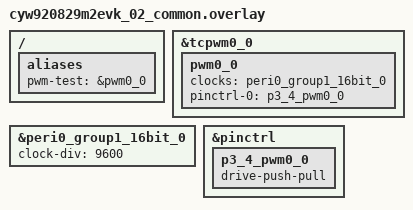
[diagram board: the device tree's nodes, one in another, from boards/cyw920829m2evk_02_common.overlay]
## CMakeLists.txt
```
# SPDX-License-Identifier: Apache-2.0

cmake_minimum_required(VERSION 3.28.0)
find_package(Zephyr REQUIRED HINTS $ENV{ZEPHYR_BASE})
project(pwm_api)

FILE(GLOB app_sources src/*.c)
target_sources(app PRIVATE ${app_sources})
```

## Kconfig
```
# Copyright (c) 2025 Tenstorrent AI ULC
# SPDX-License-Identifier: Apache-2.0

mainmenu "PWM GPIO API test"

source "Kconfig.zephyr"

config DEFAULT_PWM_PORT
	int "Default PWM port/channel"
	default 1 if PWM_STM32 || PWM_MCHP_G1_TCC || PWM_MCHP_TC_G1
	default 0
	help
	  PWM port matching the channel associated with PWM pin.

config INVALID_PWM_PORT
	int "Invalid PWM port/channel"
	default 9 if PWM_NRFX || PWM_MCHP_G1_TCC || PWM_MCHP_TC_G1
	default -1
	help
	  Invalid PWM port/channel for negative testing.

config DEFAULT_PERIOD_CYCLE
	int "Default PWM period in cycles"
	default 1024 if SOC_MK64F12 || SOC_MKW41Z4 || SOC_ESP32S2 || SOC_ESP32S3 || SOC_ESP32C3
	default 32768 if PWM_INTEL_BLINKY
	default 64000
	help
	  Default PWM period in clock cycles.

config DEFAULT_PULSE_CYCLE
	int "Default PWM pulse in cycles"
	default 512 if SOC_MK64F12 || SOC_MKW41Z4 || SOC_ESP32S2 || SOC_ESP32S3 || SOC_ESP32C3
	default 16384 if PWM_INTEL_BLINKY
	default 32000
	help
	  Default PWM pulse in clock cycles.

config DEFAULT_PERIOD_NSEC
	int "Default PWM period in nanoseconds"
	default 4000000 if SOC_FAMILY_MCXW
	default 546000 if PWM_MCHP_G1_TCC
	default 2000000
	help
	  Default PWM period in nanoseconds.

config DEFAULT_PULSE_NSEC
	int "Default PWM pulse in nanoseconds"
	default 500000 if SOC_MK64F12 || SOC_MKW41Z4 || SOC_ESP32S2 || SOC_ESP32S3 || SOC_ESP32C3
	default 500000 if PWM_INTEL_BLINKY
	default 2000000 if SOC_FAMILY_MCXW
	default 273000 if PWM_MCHP_G1_TCC
	default 1000000
	help
	  Default PWM pulse in nanoseconds.
```

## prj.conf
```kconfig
CONFIG_PWM=y
CONFIG_ZTEST=y
CONFIG_TEST_USERSPACE=y
```

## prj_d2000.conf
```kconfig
CONFIG_PWM=y
CONFIG_PINMUX=y
CONFIG_PWM_QMSI_NUM_PORTS=2
CONFIG_ZTEST=y
```

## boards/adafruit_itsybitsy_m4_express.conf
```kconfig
CONFIG_DEFAULT_PWM_PORT=2 # TCC1/WO[2] on PA18 (D7)
```

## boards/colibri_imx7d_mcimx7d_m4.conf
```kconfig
CONFIG_DEFAULT_PERIOD_CYCLE=1024
CONFIG_DEFAULT_PULSE_CYCLE=512
CONFIG_DEFAULT_PERIOD_NSEC=2000000
CONFIG_DEFAULT_PULSE_NSEC=500000
```

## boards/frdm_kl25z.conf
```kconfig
# Copyright (c) 2026 Gabriel Ivo <gabriel.bozi@usp.br>
#
# SPDX-License-Identifier: Apache-2.0

CONFIG_DEFAULT_PERIOD_CYCLE=1024
CONFIG_DEFAULT_PULSE_CYCLE=512
CONFIG_DEFAULT_PERIOD_NSEC=1000000
CONFIG_DEFAULT_PULSE_NSEC=500000
```

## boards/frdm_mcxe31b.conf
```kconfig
# Copyright 2026 NXP
# SPDX-License-Identifier: Apache-2.0

# Use eMIOS channel 3 (OPWFMB, internal counter, 10 MHz) as PWM test output.
CONFIG_DEFAULT_PWM_PORT=3
```

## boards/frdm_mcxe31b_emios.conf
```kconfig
# SPDX-FileCopyrightText: Copyright 2026 NXP
# SPDX-License-Identifier: Apache-2.0

# Use eMIOS channel 3 (OPWFMB, internal counter, 10 MHz) as PWM test output.
CONFIG_DEFAULT_PWM_PORT=3
```

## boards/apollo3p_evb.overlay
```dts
/*
 * SPDX-License-Identifier: Apache-2.0
 *
 * Copyright (c) 2025 Ambiq
 */

/ {
	aliases {
		pwm-0 = &pwm2;
	};
};

&pwm2 {
	status = "okay";
};
```

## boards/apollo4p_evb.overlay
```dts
/*
 * SPDX-License-Identifier: Apache-2.0
 *
 * Copyright (c) 2025 Ambiq
 */

/ {
	aliases {
		pwm-test = &pwm2;
	};
};

&pwm2 {
	status = "okay";
};
```

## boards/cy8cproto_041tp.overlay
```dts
/*
 * SPDX-FileCopyrightText: Copyright (c) 2026 Infineon Technologies AG,
 * SPDX-FileCopyrightText: or an affiliate of Infineon Technologies AG. All rights reserved.
 *
 * SPDX-License-Identifier: Apache-2.0
 */

#include <zephyr/dt-bindings/pwm/pwm.h>

/ {
	aliases {
		pwm-test = &pwm0_0;
	};
};

&tcpwm0_0 {
	status = "okay";

	pwm0_0 {
		clocks = <&peri_clk_div3>;
		status = "okay";
		pinctrl-0 = <&p3_1_pwm0_0>;
		pinctrl-names = "default";
	};
};

&p3_1_pwm0_0 {
	drive-push-pull;
};

&peri_clk_div3 {
	status = "okay";
};
```

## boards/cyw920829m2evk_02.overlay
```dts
/*
 * Copyright (c) 2025 Infineon Technologies AG,
 * or an affiliate of Infineon Technologies AG.
 *
 * SPDX-License-Identifier: Apache-2.0
 */

#include <zephyr/dt-bindings/pwm/pwm.h>
#include <zephyr/dt-bindings/pwm/pwm_ifx_tcpwm.h>

/ {
	aliases {
		pwm-test = &pwm0_0;
	};
};

&tcpwm0_0 {
	status = "okay";
	divider-type = <PWM_IFX_SYSCLK_DIV_16_BIT>;
	divider-sel = <1>;
	divider-val = <9599>;

	pwm0_0: pwm0_0 {
		status = "okay";
		pinctrl-0 = <&p3_4_pwm0_0>;
		pinctrl-names = "default";
	};
};

&pinctrl {
	p3_4_pwm0_0: p3_4_pwm0_0 {
		drive-push-pull;
	};
};
```

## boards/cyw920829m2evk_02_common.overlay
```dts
/*
 * SPDX-FileCopyrightText: Copyright (c) 2026 Infineon Technologies AG,
 * SPDX-FileCopyrightText: or an affiliate of Infineon Technologies AG. All rights reserved.
 *
 * SPDX-License-Identifier: Apache-2.0
 */

#include <zephyr/dt-bindings/pwm/pwm.h>
#include <zephyr/dt-bindings/pwm/pwm_ifx_tcpwm.h>

/ {
	aliases {
		pwm-test = &pwm0_0;
	};
};

&tcpwm0_0 {
	status = "okay";

	pwm0_0: pwm0_0 {
		status = "okay";
		clocks = <&peri0_group1_16bit_0>;
		pinctrl-0 = <&p3_4_pwm0_0>;
		pinctrl-names = "default";
	};
};

&peri0_group1_16bit_0 {
	status = "okay";
	clock-div = <9600>;
};

&pinctrl {
	p3_4_pwm0_0: p3_4_pwm0_0 {
		drive-push-pull;
	};
};
```

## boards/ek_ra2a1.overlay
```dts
/*
 * Copyright (c) 2025 Renesas Electronics Corporation
 *
 * SPDX-License-Identifier: Apache-2.0
 */

/ {
	aliases {
		pwm-test = &pwm0;
	};
};
```

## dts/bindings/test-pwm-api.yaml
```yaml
#
# Copyright (c) 2024 Espressif Systems (Shanghai) Co., Ltd.
#
# SPDX-License-Identifier: Apache-2.0
#

description: |
    This binding provides resources required to build and run the test
    tests/drivers/pwm/pwm_api when CONFIG_ENABLE_TIMING_CHECK is enabled.

compatible: "test-pwm-api"

properties:
  in-gpios:
    type: phandle-array
    required: true
    description: |
      GPIO to be used as input to check and validate PWM timing.
```

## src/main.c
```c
/*
 * Copyright (c) 2016 Intel Corporation
 *
 * SPDX-License-Identifier: Apache-2.0
 */


#include <zephyr/kernel.h>
#include <zephyr/ztest.h>
#include <zephyr/device.h>

const struct device *get_pwm_device(void);

static void *pwm_basic_setup(void)
{
	const struct device *dev = get_pwm_device();

	zassert_true(device_is_ready(dev), "PWM device is not ready");
	k_object_access_grant(dev, k_current_get());

	return NULL;
}

ZTEST_SUITE(pwm_basic, NULL, pwm_basic_setup, NULL, NULL, NULL);
```

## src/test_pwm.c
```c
/*
 * Copyright (c) 2016 Intel Corporation.
 *
 * SPDX-License-Identifier: Apache-2.0
 */

/**
 * @file
 * @brief Verify PWM can work well when configure through nsec,
 * or cycle.
 *
 * @details
 * - Test Steps
 *   -# Bind PWM_0 port 0.
 *   -# Set PWM period and pulse using pwm_set_cycles() or pwm_set().
 *   -# Use multimeter or other instruments to measure the output
 *	from PWM_OUT_0.
 * - Expected Results
 *   -# The output of PWM_OUT_0 will differ according to the value
 *	of period and pulse.
 *	Always on  ->  Period : Pulse (1 : 1)  ->  3.3V
 *	Half on  ->  Period : Pulse (2 : 1)  ->  1.65V
 *	Always off  ->  Period : Pulse (1 : 0)  ->  0V
 */

#include <zephyr/device.h>
#include <inttypes.h>
#include <zephyr/drivers/pwm.h>
#include <zephyr/kernel.h>
#include <zephyr/ztest.h>

#if DT_NODE_HAS_STATUS_OKAY(DT_ALIAS(pwm_test))
#define PWM_DEV_NODE DT_ALIAS(pwm_test)
#else
#error "Test requires a pwm-test alias in DTS"
#endif

#define DEFAULT_PERIOD_CYCLE CONFIG_DEFAULT_PERIOD_CYCLE
#define DEFAULT_PULSE_CYCLE  CONFIG_DEFAULT_PULSE_CYCLE
#define DEFAULT_PERIOD_NSEC  CONFIG_DEFAULT_PERIOD_NSEC
#define DEFAULT_PULSE_NSEC   CONFIG_DEFAULT_PULSE_NSEC

#if DT_HAS_COMPAT_STATUS_OKAY(zephyr_fake_pwm)
#include <zephyr/fff.h>
DEFINE_FFF_GLOBALS;
#endif

#define DEFAULT_PWM_PORT CONFIG_DEFAULT_PWM_PORT
#define INVALID_PWM_PORT CONFIG_INVALID_PWM_PORT

#define UNIT_CYCLES	0
#define UNIT_NSECS	1

const struct device *get_pwm_device(void)
{
	return DEVICE_DT_GET(PWM_DEV_NODE);
}

static int test_task(uint32_t port, uint32_t period, uint32_t pulse, uint8_t unit)
{
	TC_PRINT("[PWM]: %" PRIu8 ", [period]: %" PRIu32 ", [pulse]: %" PRIu32 "\n",
		port, period, pulse);

	const struct device *pwm_dev = get_pwm_device();

	if (!device_is_ready(pwm_dev)) {
		TC_PRINT("PWM device is not ready\n");
		return TC_FAIL;
	}

	if (unit == UNIT_CYCLES) {
		/* Verify pwm_set_cycles() */
		if (pwm_set_cycles(pwm_dev, port, period, pulse, 0)) {
			TC_PRINT("Fail to set the period and pulse width\n");
			return TC_FAIL;
		}
	} else { /* unit == UNIT_NSECS */
		/* Verify pwm_set() */
		if (pwm_set(pwm_dev, port, period, pulse, 0)) {
			TC_PRINT("Fail to set the period and pulse width\n");
			return TC_FAIL;
		}
	}

	return TC_PASS;
}

ZTEST_USER(pwm_basic, test_pwm_nsec)
{
	/* Period : Pulse (2000000 : 1000000), unit (nsec). Voltage : 1.65V */
	zassert_true(test_task(DEFAULT_PWM_PORT, DEFAULT_PERIOD_NSEC,
				DEFAULT_PULSE_NSEC, UNIT_NSECS) == TC_PASS);
	k_sleep(K_MSEC(1000));

	/* Period : Pulse (2000000 : 2000000), unit (nsec). Voltage : 3.3V */
	zassert_true(test_task(DEFAULT_PWM_PORT, DEFAULT_PERIOD_NSEC,
				DEFAULT_PERIOD_NSEC, UNIT_NSECS) == TC_PASS);
	k_sleep(K_MSEC(1000));

	/* Period : Pulse (2000000 : 0), unit (nsec). Voltage : 0V */
	zassert_true(test_task(DEFAULT_PWM_PORT, DEFAULT_PERIOD_NSEC,
				0, UNIT_NSECS) == TC_PASS);
	k_sleep(K_MSEC(1000));
}

ZTEST_USER(pwm_basic, test_pwm_cycle)
{
	/* Period : Pulse (64000 : 32000), unit (cycle). Voltage : 1.65V */
	zassert_true(test_task(DEFAULT_PWM_PORT, DEFAULT_PERIOD_CYCLE,
				DEFAULT_PULSE_CYCLE, UNIT_CYCLES) == TC_PASS);
	k_sleep(K_MSEC(1000));

	/* Period : Pulse (64000 : 64000), unit (cycle). Voltage : 3.3V */
	zassert_true(test_task(DEFAULT_PWM_PORT, DEFAULT_PERIOD_CYCLE,
				DEFAULT_PERIOD_CYCLE, UNIT_CYCLES) == TC_PASS);
	k_sleep(K_MSEC(1000));

	/* Period : Pulse (64000 : 0), unit (cycle). Voltage : 0V */
	zassert_true(test_task(DEFAULT_PWM_PORT, DEFAULT_PERIOD_CYCLE,
				0, UNIT_CYCLES) == TC_PASS);
	k_sleep(K_MSEC(1000));
}

#if (CONFIG_INVALID_PWM_PORT >= 0)
ZTEST_USER(pwm_basic, test_pwm_invalid_port)
{
	const struct device *pwm_dev = get_pwm_device();

	TC_PRINT("[PWM]: %" PRIu8 ", [period]: %" PRIu32 ", [pulse]: %" PRIu32 "\n",
		INVALID_PWM_PORT, DEFAULT_PERIOD_CYCLE, DEFAULT_PULSE_CYCLE);

	zassert_true(device_is_ready(pwm_dev), "PWM device is not ready");

	zassert_equal(pwm_set_cycles(pwm_dev, INVALID_PWM_PORT, DEFAULT_PERIOD_CYCLE,
				     DEFAULT_PULSE_CYCLE, 0),
		      -EINVAL, "Invalid PWM port\n");

}
#endif
```
